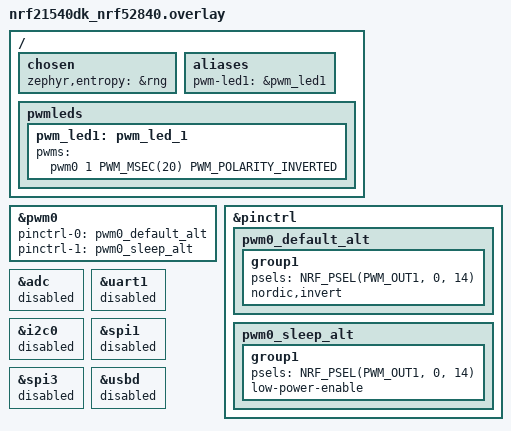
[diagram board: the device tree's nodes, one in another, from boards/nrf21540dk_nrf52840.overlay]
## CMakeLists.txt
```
#
# Copyright (c) 2021 Nordic Semiconductor ASA
#
# SPDX-License-Identifier: LicenseRef-Nordic-5-Clause
#

cmake_minimum_required(VERSION 3.20.0)

find_package(Zephyr HINTS $ENV{ZEPHYR_BASE})

project(matter-light-bulb)

# Enable GNU STD support and initialize the Matter Data Model.
include(${ZEPHYR_CONNECTEDHOMEIP_MODULE_DIR}/config/nrfconnect/app/enable-gnu-std.cmake)
include(${ZEPHYR_CONNECTEDHOMEIP_MODULE_DIR}/src/app/chip_data_model.cmake)

# NORDIC SDK APP START

# Include all source files that are located in the Matter common directory.
include(${ZEPHYR_NRF_MODULE_DIR}/samples/matter/common/cmake/source_common.cmake)

target_include_directories(app PRIVATE
    src
    ${CONFIG_NCS_SAMPLE_MATTER_ZAP_FILES_PATH}
)

if(CONFIG_AWS_IOT_INTEGRATION)
    add_subdirectory(src/aws_iot_integration)
endif()

target_sources(app PRIVATE
    src/app_task.cpp
    src/main.cpp
    src/zcl_callbacks.cpp
)

chip_configure_data_model(app
    INCLUDE_SERVER
    BYPASS_IDL
    GEN_DIR ${CONFIG_NCS_SAMPLE_MATTER_ZAP_FILES_PATH}/zap-generated
    ZAP_FILE ${CMAKE_CURRENT_SOURCE_DIR}/${CONFIG_NCS_SAMPLE_MATTER_ZAP_FILES_PATH}/light_bulb.zap
)
# NORDIC SDK APP END
```

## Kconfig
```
#
# Copyright (c) 2022 Nordic Semiconductor
#
# SPDX-License-Identifier: LicenseRef-Nordic-5-Clause
#
mainmenu "Matter nRF Connect Light Bulb Example Application"

# Sample configuration used for Thread networking
if NET_L2_OPENTHREAD

choice OPENTHREAD_NORDIC_LIBRARY_CONFIGURATION
	default OPENTHREAD_NORDIC_LIBRARY_FTD
endchoice

choice OPENTHREAD_DEVICE_TYPE
	default OPENTHREAD_FTD
endchoice

endif # NET_L2_OPENTHREAD

source "${ZEPHYR_CONNECTEDHOMEIP_MODULE_DIR}/config/nrfconnect/chip-module/Kconfig.features"
source "${ZEPHYR_CONNECTEDHOMEIP_MODULE_DIR}/config/nrfconnect/chip-module/Kconfig.defaults"
source "${ZEPHYR_NRF_MODULE_DIR}/samples/matter/common/src/Kconfig"
source "Kconfig.zephyr"
rsource "src/aws_iot_integration/Kconfig"
```

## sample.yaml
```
sample:
  description: Matter Light Bulb example
  name: Matter Light Bulb
tests:
  sample.matter.light_bulb.debug:
    sysbuild: true
    build_only: true
    integration_platforms:
      - nrf52840dk/nrf52840
      - nrf5340dk/nrf5340/cpuapp
      - nrf7002dk/nrf5340/cpuapp
      - nrf54l15dk/nrf54l15/cpuapp
      - nrf54l15dk/nrf54l15/cpuapp/ns
    platform_allow: nrf52840dk/nrf52840 nrf5340dk/nrf5340/cpuapp nrf7002dk/nrf5340/cpuapp
      nrf54l15dk/nrf54l15/cpuapp nrf54l15dk/nrf54l15/cpuapp/ns
    tags: sysbuild ci_samples_matter
  sample.matter.light_bulb.release:
    sysbuild: true
    build_only: true
    extra_args: FILE_SUFFIX=release
      SB_CONFIG_BOOTLOADER_MCUBOOT=y SB_CONFIG_PARTITION_MANAGER=y
    integration_platforms:
      - nrf52840dk/nrf52840
      - nrf5340dk/nrf5340/cpuapp
      - nrf7002dk/nrf5340/cpuapp
      - nrf54l15dk/nrf54l15/cpuapp
    platform_allow: nrf52840dk/nrf52840 nrf5340dk/nrf5340/cpuapp nrf7002dk/nrf5340/cpuapp
      nrf54l15dk/nrf54l15/cpuapp
    tags: sysbuild ci_samples_matter
  sample.matter.light_bulb.lto:
    sysbuild: true
    build_only: true
    extra_args: CONFIG_LTO=y CONFIG_ISR_TABLES_LOCAL_DECLARATION=y
    integration_platforms:
      - nrf52840dk/nrf52840
      - nrf5340dk/nrf5340/cpuapp
      - nrf7002dk/nrf5340/cpuapp
      - nrf54l15dk/nrf54l15/cpuapp
    platform_allow: nrf52840dk/nrf52840 nrf5340dk/nrf5340/cpuapp nrf7002dk/nrf5340/cpuapp
      nrf54l15dk/nrf54l15/cpuapp
    tags: sysbuild ci_samples_matter
  sample.matter.light_bulb.ffs:
    sysbuild: true
    build_only: true
    extra_args: >
      CONFIG_CHIP_COMMISSIONABLE_DEVICE_TYPE=y CONFIG_CHIP_ROTATING_DEVICE_ID=y
      CONFIG_CHIP_DEVICE_TYPE=257
    integration_platforms:
      - nrf52840dk/nrf52840
      - nrf5340dk/nrf5340/cpuapp
      - nrf7002dk/nrf5340/cpuapp
      - nrf54l15dk/nrf54l15/cpuapp
    platform_allow: nrf52840dk/nrf52840 nrf5340dk/nrf5340/cpuapp nrf7002dk/nrf5340/cpuapp
      nrf54l15dk/nrf54l15/cpuapp
    tags: sysbuild ci_samples_matter
  sample.matter.light_bulb.debug.nrf21540ek:
    sysbuild: true
    build_only: true
    extra_args: light_bulb_SHIELD=nrf21540ek
    integration_platforms:
      - nrf52840dk/nrf52840
    platform_allow: nrf52840dk/nrf52840
    tags: sysbuild ci_samples_matter
  sample.matter.light_bulb.debug.nrf21540ek_fwd:
    sysbuild: true
    build_only: true
    extra_args: light_bulb_SHIELD=nrf21540ek multiprotocol_rpmsg_SHIELD=nrf21540ek
    integration_platforms:
      - nrf5340dk/nrf5340/cpuapp
    platform_allow: nrf5340dk/nrf5340/cpuapp
    tags: sysbuild ci_samples_matter
  # Sample to execute load tests
  sample.matter.light_bulb.memory_profiling.persistent_subscriptions:
    sysbuild: true
    build_only: true
    extra_args: CONFIG_CHIP_PERSISTENT_SUBSCRIPTIONS=y
      CONFIG_CHIP_MEMORY_PROFILING=y CONFIG_SHELL_MINIMAL=y
    platform_allow: nrf52840dk/nrf52840 nrf5340dk/nrf5340/cpuapp
      nrf54l15dk/nrf54l15/cpuapp
    integration_platforms:
      - nrf52840dk/nrf52840
      - nrf5340dk/nrf5340/cpuapp
      - nrf54l15dk/nrf54l15/cpuapp
    tags: sysbuild ci_samples_matter
  sample.matter.light_bulb.lto.memory_profiling.persistent_subscriptions:
    sysbuild: true
    build_only: true
    extra_args: CONFIG_CHIP_PERSISTENT_SUBSCRIPTIONS=y
      CONFIG_CHIP_MEMORY_PROFILING=y CONFIG_SHELL_MINIMAL=y CONFIG_LTO=y
      CONFIG_ISR_TABLES_LOCAL_DECLARATION=y
    platform_allow: nrf7002dk/nrf5340/cpuapp
    integration_platforms:
      - nrf7002dk/nrf5340/cpuapp
    tags: sysbuild ci_samples_matter
  sample.matter.light_bulb.aws:
    sysbuild: true
    build_only: true
    extra_args: EXTRA_CONF_FILE="overlay-aws-iot-integration.conf"
    platform_allow: nrf7002dk/nrf5340/cpuapp
    integration_platforms:
      - nrf7002dk/nrf5340/cpuapp
    tags: sysbuild ci_samples_matter
```

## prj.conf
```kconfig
#
# Copyright (c) 2022 Nordic Semiconductor ASA
#
# SPDX-License-Identifier: LicenseRef-Nordic-5-Clause
#

# Enable CHIP
CONFIG_CHIP=y
CONFIG_CHIP_PROJECT_CONFIG="src/chip_project_config.h"
# 32773 == 0x8005 (example lighting-app)
CONFIG_CHIP_DEVICE_PRODUCT_ID=32773
CONFIG_STD_CPP17=y

# Enable Matter pairing automatically on application start.
CONFIG_CHIP_ENABLE_PAIRING_AUTOSTART=y

# Enable Matter extended announcement and increase duration to 1 hour.
CONFIG_CHIP_BLE_EXT_ADVERTISING=y
CONFIG_CHIP_BLE_ADVERTISING_DURATION=60

# Add support for LEDs and buttons on Nordic development kits
CONFIG_DK_LIBRARY=y
CONFIG_PWM=y

# Bluetooth Low Energy configuration
CONFIG_BT_DEVICE_NAME="MatterLight"

# Other settings
CONFIG_THREAD_NAME=y
CONFIG_MPU_STACK_GUARD=y
CONFIG_RESET_ON_FATAL_ERROR=n
CONFIG_CHIP_LIB_SHELL=y
CONFIG_NCS_SAMPLE_MATTER_TEST_SHELL=y

# Reduce application size
CONFIG_USE_SEGGER_RTT=n

# Enable Factory Data feature
CONFIG_CHIP_FACTORY_DATA=y
CONFIG_CHIP_FACTORY_DATA_BUILD=y
```

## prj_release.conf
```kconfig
#
# Copyright (c) 2022 Nordic Semiconductor ASA
#
# SPDX-License-Identifier: LicenseRef-Nordic-5-Clause
#

# Enable CHIP
CONFIG_CHIP=y
CONFIG_CHIP_PROJECT_CONFIG="src/chip_project_config.h"
# 32773 == 0x8005 (example lighting-app)
CONFIG_CHIP_DEVICE_PRODUCT_ID=32773
CONFIG_STD_CPP17=y

# Enable Matter pairing automatically on application start.
CONFIG_CHIP_ENABLE_PAIRING_AUTOSTART=y

# Enable Matter extended announcement and increase duration to 1 hour.
CONFIG_CHIP_BLE_EXT_ADVERTISING=y
CONFIG_CHIP_BLE_ADVERTISING_DURATION=60

# Add support for LEDs and buttons on Nordic development kits
CONFIG_DK_LIBRARY=y
CONFIG_PWM=y

# Bluetooth Low Energy configuration
CONFIG_BT_DEVICE_NAME="MatterLight"

# Enable system reset on fatal error
CONFIG_RESET_ON_FATAL_ERROR=y

# Disable all debug features
CONFIG_USE_SEGGER_RTT=n
CONFIG_SHELL=n
CONFIG_OPENTHREAD_SHELL=n
CONFIG_CONSOLE=n
CONFIG_UART_CONSOLE=n
CONFIG_SERIAL=n
CONFIG_LOG=n
CONFIG_LOG_MODE_MINIMAL=n
CONFIG_ASSERT_VERBOSE=n
CONFIG_ASSERT_NO_FILE_INFO=y
CONFIG_PRINTK=n
CONFIG_PRINTK_SYNC=n
CONFIG_THREAD_NAME=n
CONFIG_BOOT_BANNER=n

# Enable Factory Data feature
CONFIG_CHIP_FACTORY_DATA=y
CONFIG_CHIP_FACTORY_DATA_BUILD=y

# Enable Watchdog
CONFIG_NCS_SAMPLE_MATTER_WATCHDOG=y
```

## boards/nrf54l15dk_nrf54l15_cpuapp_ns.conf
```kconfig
#
# Copyright (c) 2024 Nordic Semiconductor ASA
#
# SPDX-License-Identifier: LicenseRef-Nordic-5-Clause
#

# Multirole is the only currently supported role by SoftDevice.
CONFIG_BT_LL_SOFTDEVICE_MULTIROLE=y

# TODO: Workaround to be removed once Zephyr's CONFIG_FPROTECT is supported on nRF54L_ns
CONFIG_CHIP_FACTORY_DATA_WRITE_PROTECT=n

# TODO: KRKNWK-19382: Disable NFC commissioning due to an issue with definitions for ns build.
CONFIG_CHIP_NFC_COMMISSIONING=n

# nRF54L15 requires bigger stack sizes than nRF52/nRF53 families
CONFIG_CHIP_MALLOC_SYS_HEAP_SIZE=10240
CONFIG_MPSL_WORK_STACK_SIZE=2048

# Set the ZMS sector count to match the settings partition size that is 40 kB for this application.
CONFIG_SETTINGS_ZMS_SECTOR_COUNT=10
# Workaround required as Zephyr L2 implies usage of NVS backend for settings.
# It should be removed once the proper fix will be applied in Zephyr.
CONFIG_NVS=n
```

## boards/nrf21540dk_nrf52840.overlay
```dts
/*
 * Copyright (c) 2021-2022 Nordic Semiconductor ASA
 *
 * SPDX-License-Identifier: LicenseRef-Nordic-5-Clause
 */

/ {
	/*
	* In some default configurations within the nRF Connect SDK,
	* e.g. on nRF52840, the chosen zephyr,entropy node is &cryptocell.
	* This devicetree overlay ensures that default is overridden wherever it
	* is set, as this application uses the RNG node for entropy exclusively.
	*/

	chosen {
		zephyr,entropy = &rng;
	};

	/*
	* By default, PWM module is only configured for led0 (LED1 on the board).
	* The light bulb app, however, uses LED2 to show the state of the lighting,
	* including its brightness level.
	*/
	aliases {
		pwm-led1 = &pwm_led1;
	};

	pwmleds {
		pwm_led1: pwm_led_1 {
			pwms = <&pwm0 1 PWM_MSEC(20) PWM_POLARITY_INVERTED>;
		};
	};

};

&pwm0 {
	pinctrl-0 = <&pwm0_default_alt>;
	pinctrl-1 = <&pwm0_sleep_alt>;
	pinctrl-names = "default", "sleep";
};

&pinctrl {
	pwm0_default_alt: pwm0_default_alt {
		group1 {
			psels = <NRF_PSEL(PWM_OUT1, 0, 14)>;
			nordic,invert;
		};
	};

	pwm0_sleep_alt: pwm0_sleep_alt {
		group1 {
			psels = <NRF_PSEL(PWM_OUT1, 0, 14)>;
			low-power-enable;
		};
	};

};

/* Disable unused peripherals to reduce power consumption */
&adc {
	status = "disabled";
};
&uart1 {
	status = "disabled";
};
&i2c0 {
	status = "disabled";
};
&spi1 {
	status = "disabled";
};
&spi3 {
	status = "disabled";
};
&usbd {
	status = "disabled";
};
```

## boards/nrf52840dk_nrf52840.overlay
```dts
/*
 * Copyright (c) 2021-2022 Nordic Semiconductor ASA
 *
 * SPDX-License-Identifier: LicenseRef-Nordic-5-Clause
 */

/ {
	chosen {
		nordic,pm-ext-flash = &mx25r64;
	};

	/*
	* In some default configurations within the nRF Connect SDK,
	* e.g. on nRF52840, the chosen zephyr,entropy node is &cryptocell.
	* This devicetree overlay ensures that default is overridden wherever it
	* is set, as this application uses the RNG node for entropy exclusively.
	*/

	chosen {
		zephyr,entropy = &rng;
	};

	/*
	* By default, PWM module is only configured for led0 (LED1 on the board).
	* The light bulb app, however, uses LED2 to show the state of the lighting,
	* including its brightness level.
	*/
	aliases {
		pwm-led1 = &pwm_led1;
	};

	pwmleds {
		pwm_led1: pwm_led_1 {
			pwms = <&pwm0 1 PWM_MSEC(20) PWM_POLARITY_INVERTED>;
		};
	};

};

&pwm0 {
	pinctrl-0 = <&pwm0_default_alt>;
	pinctrl-1 = <&pwm0_sleep_alt>;
	pinctrl-names = "default", "sleep";
};

&pinctrl {
	pwm0_default_alt: pwm0_default_alt {
		group1 {
			psels = <NRF_PSEL(PWM_OUT1, 0, 14)>;
			nordic,invert;
		};
	};

	pwm0_sleep_alt: pwm0_sleep_alt {
		group1 {
			psels = <NRF_PSEL(PWM_OUT1, 0, 14)>;
			low-power-enable;
		};
	};

};

/* Disable unused peripherals to reduce power consumption */
&adc {
	status = "disabled";
};
&uart1 {
	status = "disabled";
};
&i2c0 {
	status = "disabled";
};
&spi1 {
	status = "disabled";
};
&spi3 {
	status = "disabled";
};
&usbd {
	status = "disabled";
};
```

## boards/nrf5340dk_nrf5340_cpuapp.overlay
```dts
/*
 * Copyright (c) 2021-2022 Nordic Semiconductor ASA
 *
 * SPDX-License-Identifier: LicenseRef-Nordic-5-Clause
 */

#include <zephyr/dt-bindings/ipc_service/static_vrings.h>

/ {
	chosen {
		nordic,pm-ext-flash = &mx25r64;
	};

	/*
	* By default, PWM module is only configured for led0 (LED1 on the board).
	* The light bulb app, however, uses LED2 to show the state of the lighting,
	* including its brightness level.
	*/
	aliases {
		pwm-led1 = &pwm_led1;
	};

	pwmleds {
		compatible = "pwm-leds";
		pwm_led1: pwm_led_1 {
			pwms = < &pwm0 1 PWM_MSEC(20) PWM_POLARITY_INVERTED>;
		};
	};
};

/* Set IPC thread priority to the highest value to not collide with other threads. */
&ipc0 {
    zephyr,priority = <0 PRIO_COOP>;
};

&pwm0 {
	pinctrl-0 = <&pwm0_default_alt>;
	pinctrl-1 = <&pwm0_sleep_alt>;
	pinctrl-names = "default", "sleep";
};

&pinctrl {
	pwm0_default_alt: pwm0_default_alt {
		group1 {
			psels = <NRF_PSEL(PWM_OUT1, 0, 29)>;
			nordic,invert;
		};
	};

	pwm0_sleep_alt: pwm0_sleep_alt {
		group1 {
			psels = <NRF_PSEL(PWM_OUT1, 0, 29)>;
			low-power-enable;
		};
	};
};

/* Disable unused peripherals to reduce power consumption */
&adc {
	status = "disabled";
};
&i2c1 {
	status = "disabled";
};
&spi2 {
	status = "disabled";
};
&usbd {
	status = "disabled";
};
```

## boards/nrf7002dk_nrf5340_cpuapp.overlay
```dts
/*
 * Copyright (c) 2022 Nordic Semiconductor ASA
 *
 * SPDX-License-Identifier: LicenseRef-Nordic-5-Clause
 */

#include <zephyr/dt-bindings/ipc_service/static_vrings.h>

/ {
	chosen {
		nordic,pm-ext-flash = &mx25r64;
	};

	/*
	* By default, PWM module is only configured for led0 (LED1 on the board).
	* The light bulb app, however, uses LED2 to show the state of the lighting,
	* including its brightness level.
	*/
	aliases {
		pwm-led1 = &pwm_led1;
		watchdog0 = &wdt0;
	};

	pwmleds {
		compatible = "pwm-leds";
		pwm_led1: pwm_led_1 {
			pwms = < &pwm0 1 PWM_MSEC(20) PWM_POLARITY_NORMAL>;
		};
	};
};

/* Set IPC thread priority to the highest value to not collide with other threads. */
&ipc0 {
    zephyr,priority = <0 PRIO_COOP>;
};

&pwm0 {
	pinctrl-0 = <&pwm0_default_alt>;
	pinctrl-1 = <&pwm0_sleep_alt>;
	pinctrl-names = "default", "sleep";
};

&pinctrl {
	pwm0_default_alt: pwm0_default_alt {
		group1 {
			psels = <NRF_PSEL(PWM_OUT1, 1, 7)>;
			nordic,invert;
		};
	};

	pwm0_sleep_alt: pwm0_sleep_alt {
		group1 {
			psels = <NRF_PSEL(PWM_OUT1, 1, 7)>;
			low-power-enable;
		};
	};

};
```

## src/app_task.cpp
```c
/*
 * Copyright (c) 2021 Nordic Semiconductor ASA
 *
 * SPDX-License-Identifier: LicenseRef-Nordic-5-Clause
 */

#include "app_task.h"

#ifdef CONFIG_AWS_IOT_INTEGRATION
#include "aws_iot_integration.h"
#endif

#include "app/matter_init.h"
#include "app/task_executor.h"

#if defined(CONFIG_PWM)
#include "pwm/pwm_device.h"
#endif

#ifdef CONFIG_CHIP_OTA_REQUESTOR
#include "dfu/ota/ota_util.h"
#endif

#include <app-common/zap-generated/attributes/Accessors.h>
#include <app/DeferredAttributePersistenceProvider.h>
#include <app/clusters/identify-server/identify-server.h>
#include <app/server/OnboardingCodesUtil.h>
#include <app/server/Server.h>

#include <zephyr/logging/log.h>

LOG_MODULE_DECLARE(app, CONFIG_CHIP_APP_LOG_LEVEL);

using namespace ::chip;
using namespace ::chip::app;
using namespace ::chip::DeviceLayer;

namespace
{
constexpr EndpointId kLightEndpointId = 1;
constexpr uint8_t kDefaultMinLevel = 0;
constexpr uint8_t kDefaultMaxLevel = 254;
constexpr uint16_t kTriggerEffectTimeout = 5000;
constexpr uint16_t kTriggerEffectFinishTimeout = 1000;

k_timer sTriggerEffectTimer;

Identify sIdentify = { kLightEndpointId, AppTask::IdentifyStartHandler, AppTask::IdentifyStopHandler,
		       Clusters::Identify::IdentifyTypeEnum::kVisibleIndicator, AppTask::TriggerIdentifyEffectHandler };

bool sIsTriggerEffectActive = false;

#if defined(CONFIG_PWM)
const struct pwm_dt_spec sLightPwmDevice = PWM_DT_SPEC_GET(DT_ALIAS(pwm_led1));
#endif

// Define a custom attribute persister which makes actual write of the CurrentLevel attribute value
// to the non-volatile storage only when it has remained constant for 5 seconds. This is to reduce
// the flash wearout when the attribute changes frequently as a result of MoveToLevel command.
// DeferredAttribute object describes a deferred attribute, but also holds a buffer with a value to
// be written, so it must live so long as the DeferredAttributePersistenceProvider object.
DeferredAttribute gCurrentLevelPersister(ConcreteAttributePath(kLightEndpointId, Clusters::LevelControl::Id,
							       Clusters::LevelControl::Attributes::CurrentLevel::Id));
DeferredAttributePersistenceProvider gDeferredAttributePersister(Server::GetInstance().GetDefaultAttributePersister(),
								 Span<DeferredAttribute>(&gCurrentLevelPersister, 1),
								 System::Clock::Milliseconds32(5000));

#define APPLICATION_BUTTON_MASK DK_BTN2_MSK
} /* namespace */

void AppTask::IdentifyStartHandler(Identify *)
{
	Nrf::PostTask(
		[] { Nrf::GetBoard().GetLED(Nrf::DeviceLeds::LED2).Blink(Nrf::LedConsts::kIdentifyBlinkRate_ms); });
}

void AppTask::IdentifyStopHandler(Identify *)
{
	Nrf::PostTask([] {
		Nrf::GetBoard().GetLED(Nrf::DeviceLeds::LED2).Set(false);

#if defined(CONFIG_PWM)
		Instance().mPWMDevice.ApplyLevel();
#endif
	});
}

void AppTask::TriggerEffectTimerTimeoutCallback(k_timer *timer)
{
	LOG_INF("Identify effect completed");

	sIsTriggerEffectActive = false;

	Nrf::GetBoard().GetLED(Nrf::DeviceLeds::LED2).Set(false);

#if defined(CONFIG_PWM)
	Instance().mPWMDevice.ApplyLevel();
#endif
}

void AppTask::TriggerIdentifyEffectHandler(Identify *identify)
{
	switch (identify->mCurrentEffectIdentifier) {
	/* Just handle all effects in the same way. */
	case Clusters::Identify::EffectIdentifierEnum::kBlink:
	case Clusters::Identify::EffectIdentifierEnum::kBreathe:
	case Clusters::Identify::EffectIdentifierEnum::kOkay:
	case Clusters::Identify::EffectIdentifierEnum::kChannelChange:
		LOG_INF("Identify effect identifier changed to %d",
			static_cast<uint8_t>(identify->mCurrentEffectIdentifier));

		sIsTriggerEffectActive = false;

		k_timer_stop(&sTriggerEffectTimer);
		k_timer_start(&sTriggerEffectTimer, K_MSEC(kTriggerEffectTimeout), K_NO_WAIT);

#if defined(CONFIG_PWM)
		Instance().mPWMDevice.SuppressOutput();
#endif
		Nrf::GetBoard().GetLED(Nrf::DeviceLeds::LED2).Blink(Nrf::LedConsts::kIdentifyBlinkRate_ms);

		break;
	case Clusters::Identify::EffectIdentifierEnum::kFinishEffect:
		LOG_INF("Identify effect finish triggered");
		k_timer_stop(&sTriggerEffectTimer);
		k_timer_start(&sTriggerEffectTimer, K_MSEC(kTriggerEffectFinishTimeout), K_NO_WAIT);
		break;
	case Clusters::Identify::EffectIdentifierEnum::kStopEffect:
		if (sIsTriggerEffectActive) {
			sIsTriggerEffectActive = false;

			k_timer_stop(&sTriggerEffectTimer);

			Nrf::GetBoard().GetLED(Nrf::DeviceLeds::LED2).Set(false);

#if defined(CONFIG_PWM)
			Instance().mPWMDevice.ApplyLevel();
#endif
		}
		break;
	default:
		LOG_ERR("Received invalid effect identifier.");
		break;
	}
}

void AppTask::LightingActionEventHandler(const LightingEvent &event)
{
#if defined(CONFIG_PWM)
	Nrf::PWMDevice::Action_t action = Nrf::PWMDevice::INVALID_ACTION;
	int32_t actor = 0;
	if (event.Actor == LightingActor::Button) {
		action = Instance().mPWMDevice.IsTurnedOn() ? Nrf::PWMDevice::OFF_ACTION : Nrf::PWMDevice::ON_ACTION;
		actor = static_cast<int32_t>(event.Actor);
	}

	if (action == Nrf::PWMDevice::INVALID_ACTION || !Instance().mPWMDevice.InitiateAction(action, actor, NULL)) {
		LOG_INF("An action could not be initiated.");
	}
#else
	Nrf::GetBoard().GetLED(Nrf::DeviceLeds::LED2).Set(!Nrf::GetBoard().GetLED(Nrf::DeviceLeds::LED2).GetState());
#endif
}

void AppTask::ButtonEventHandler(Nrf::ButtonState state, Nrf::ButtonMask hasChanged)
{
	if ((APPLICATION_BUTTON_MASK & hasChanged) & state) {
		Nrf::PostTask([] {
			LightingEvent event;
			event.Actor = LightingActor::Button;
			LightingActionEventHandler(event);
		});
	}
}

#ifdef CONFIG_AWS_IOT_INTEGRATION
bool AppTask::AWSIntegrationCallback(struct aws_iot_integration_cb_data *data)
{
	LOG_INF("Attribute change requested from AWS IoT: %d", data->value);

	Protocols::InteractionModel::Status status;

	VerifyOrDie(data->error == 0);

	if (data->attribute_id == ATTRIBUTE_ID_ONOFF) {
		/* write the new on/off value */
		status = Clusters::OnOff::Attributes::OnOff::Set(kLightEndpointId, data->value);
		if (status != Protocols::InteractionModel::Status::Success) {
			LOG_ERR("Updating on/off cluster failed: %x", to_underlying(status));
			return false;
		}
	} else if (data->attribute_id == ATTRIBUTE_ID_LEVEL_CONTROL) {
		/* write the current level */
		status = Clusters::LevelControl::Attributes::CurrentLevel::Set(kLightEndpointId, data->value);

		if (status != Protocols::InteractionModel::Status::Success) {
			LOG_ERR("Updating level cluster failed: %x", to_underlying(status));
			return false;
		}
	}

	return true;
}
#endif /* CONFIG_AWS_IOT_INTEGRATION */

#if defined(CONFIG_PWM)
void AppTask::ActionInitiated(Nrf::PWMDevice::Action_t action, int32_t actor)
{
	if (action == Nrf::PWMDevice::ON_ACTION) {
		LOG_INF("Turn On Action has been initiated");
	} else if (action == Nrf::PWMDevice::OFF_ACTION) {
		LOG_INF("Turn Off Action has been initiated");
	} else if (action == Nrf::PWMDevice::LEVEL_ACTION) {
		LOG_INF("Level Action has been initiated");
	}
}

void AppTask::ActionCompleted(Nrf::PWMDevice::Action_t action, int32_t actor)
{
	if (action == Nrf::PWMDevice::ON_ACTION) {
		LOG_INF("Turn On Action has been completed");
	} else if (action == Nrf::PWMDevice::OFF_ACTION) {
		LOG_INF("Turn Off Action has been completed");
	} else if (action == Nrf::PWMDevice::LEVEL_ACTION) {
		LOG_INF("Level Action has been completed");
	}

	if (actor == static_cast<int32_t>(LightingActor::Button)) {
		Instance().UpdateClusterState();
	}
}
#endif /* CONFIG_PWM */

void AppTask::UpdateClusterState()
{
	SystemLayer().ScheduleLambda([this] {
#if defined(CONFIG_PWM)
		/* write the new on/off value */
		Protocols::InteractionModel::Status status =
			Clusters::OnOff::Attributes::OnOff::Set(kLightEndpointId, mPWMDevice.IsTurnedOn());
#else
		Protocols::InteractionModel::Status status = Clusters::OnOff::Attributes::OnOff::Set(
			kLightEndpointId, Nrf::GetBoard().GetLED(Nrf::DeviceLeds::LED2).GetState());
#endif
		if (status != Protocols::InteractionModel::Status::Success) {
			LOG_ERR("Updating on/off cluster failed: %x", to_underlying(status));
		}

#if defined(CONFIG_PWM)
		/* write the current level */
		status = Clusters::LevelControl::Attributes::CurrentLevel::Set(kLightEndpointId, mPWMDevice.GetLevel());
#else
		/* write the current level */
		if (Nrf::GetBoard().GetLED(Nrf::DeviceLeds::LED2).GetState()) {
			status = Clusters::LevelControl::Attributes::CurrentLevel::Set(kLightEndpointId, 100);
		} else {
			status = Clusters::LevelControl::Attributes::CurrentLevel::Set(kLightEndpointId, 0);
		}
#endif

		if (status != Protocols::InteractionModel::Status::Success) {
			LOG_ERR("Updating level cluster failed: %x", to_underlying(status));
		}
	});
}

void AppTask::InitPWMDDevice()
{
#if defined(CONFIG_PWM)
	/* Initialize lighting device (PWM) */
	uint8_t minLightLevel = kDefaultMinLevel;
	Clusters::LevelControl::Attributes::MinLevel::Get(kLightEndpointId, &minLightLevel);

	uint8_t maxLightLevel = kDefaultMaxLevel;
	Clusters::LevelControl::Attributes::MaxLevel::Get(kLightEndpointId, &maxLightLevel);

	Clusters::LevelControl::Attributes::CurrentLevel::TypeInfo::Type currentLevel;
	Clusters::LevelControl::Attributes::CurrentLevel::Get(kLightEndpointId, currentLevel);

	int ret =
		mPWMDevice.Init(&sLightPwmDevice, minLightLevel, maxLightLevel, currentLevel.ValueOr(kDefaultMaxLevel));
	if (ret != 0) {
		LOG_ERR("Failed to initialize PWD device.");
	}

	mPWMDevice.SetCallbacks(ActionInitiated, ActionCompleted);
#endif
}

CHIP_ERROR AppTask::Init()
{
	/* Initialize Matter stack */
	ReturnErrorOnFailure(Nrf::Matter::PrepareServer(Nrf::Matter::InitData{ .mPostServerInitClbk = [] {
		app::SetAttributePersistenceProvider(&gDeferredAttributePersister);
		return CHIP_NO_ERROR;
	} }));

	if (!Nrf::GetBoard().Init(ButtonEventHandler)) {
		LOG_ERR("User interface initialization failed.");
		return CHIP_ERROR_INCORRECT_STATE;
	}

	/* Register Matter event handler that controls the connectivity status LED based on the captured Matter network
	 * state. */
	ReturnErrorOnFailure(Nrf::Matter::RegisterEventHandler(Nrf::Board::DefaultMatterEventHandler, 0));

#ifdef CONFIG_AWS_IOT_INTEGRATION
	int retAws = aws_iot_integration_register_callback(AWSIntegrationCallback);
	if (retAws) {
		LOG_ERR("aws_iot_integration_register_callback() failed");
		return chip::System::MapErrorZephyr(retAws);
	}
#endif

	/* Initialize trigger effect timer */
	k_timer_init(&sTriggerEffectTimer, &AppTask::TriggerEffectTimerTimeoutCallback, nullptr);

	return Nrf::Matter::StartServer();
}

CHIP_ERROR AppTask::StartApp()
{
	ReturnErrorOnFailure(Init());

	while (true) {
		Nrf::DispatchNextTask();
	}

	return CHIP_NO_ERROR;
}
```
